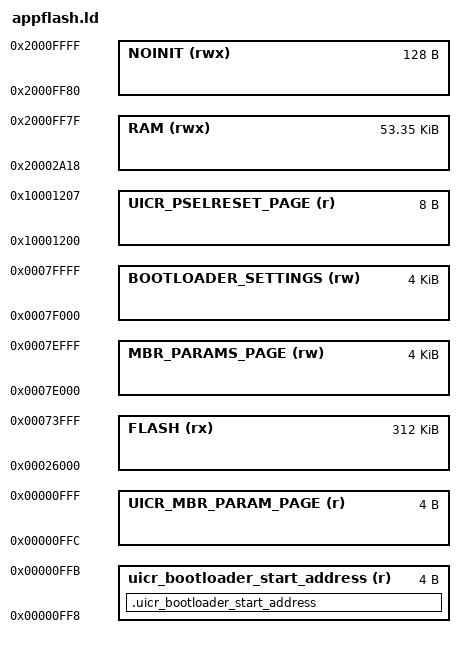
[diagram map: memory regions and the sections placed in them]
/*
 * application specific linker script (starts at 0X2080 (ram) 0x1f000 (Flash) )
 */

SEARCH_DIR(.)
GROUP(-lgcc -lc -lnosys)

MEMORY
{
  FLASH (rx) : ORIGIN = 0x26000, LENGTH = 0x4E000

  /**
   * Leave 80 bytes to the end of RAM for over reset info (NOINIT)
   */
  RAM (rwx) :  ORIGIN = 0x20002A18, LENGTH = 0xD568

  /** Location of non initialized RAM. Non initialized RAM is used for exchanging bond information
   *  from application to bootloader when using buttonluss DFU OTA.
   */
  NOINIT (rwx) :  ORIGIN = 0x2000FF80, LENGTH = 0x80

  /** Location of bootloader setting in flash. */
  BOOTLOADER_SETTINGS (rw) : ORIGIN = 0x0007F000, LENGTH = 0x1000

  /** Location in UICR where bootloader start address is stored. */
  uicr_bootloader_start_address (r) : ORIGIN = 0x00000FF8, LENGTH = 0x4

  /** Location of mbr params page in flash. */
  MBR_PARAMS_PAGE (rw) : ORIGIN = 0x0007E000, LENGTH = 0x1000

  /** Location in UICR where mbr params page address is stored. */
  UICR_MBR_PARAM_PAGE(r) : ORIGIN = 0x00000FFC, LENGTH = 0x04

  /** Location in UICR where PSELRESET params settings are stored. */
  UICR_PSELRESET_PAGE(r) : ORIGIN = 0x10001200, LENGTH = 0x08
}

SECTIONS
{
  . = ALIGN(4);
  .uicr_bootloader_start_address :
  {
    PROVIDE(__start_uicr_bootloader_start_address = .);
    KEEP(*(SORT(.uicr_bootloader_start_address*)))
    PROVIDE(__stop_uicr_bootloader_start_address = .);
  } > uicr_bootloader_start_address
}

SECTIONS
{
  /* Place the bootloader settings page in flash. */
  .bootloaderSettings(NOLOAD) :
  {

  } > BOOTLOADER_SETTINGS

  /* Place the mbr params page in flash. */
    .mbrParamsPage(NOLOAD) :
  {

  } > MBR_PARAMS_PAGE

  /* Write the bootloader address in UICR. */
  .uicrMbrParamsPageAddress :
  {
    KEEP(*(.uicrMbrParamsPageAddress))
  } > UICR_MBR_PARAM_PAGE


  /* Write RESET pin settings (dissable RESET pin) in UICR */
  .uicrPselresetPage :
  {
    KEEP(*(.uicrPselresetPage))
  } > UICR_PSELRESET_PAGE

  /* No init RAM section. Used for stuff like timestorage & faultcom. */
  .timestorage(NOLOAD) :
  {
  } > NOINIT
  .faultcom(NOLOAD) :
  {
  } > NOINIT

  .fs_data :
  {
    PROVIDE(__start_fs_data = .);
    KEEP(*(.fs_data))
    PROVIDE(__stop_fs_data = .);
  } > RAM
} INSERT AFTER .data;


SECTIONS
{
  . = ALIGN(4);
  .mem_section_dummy_ram :
  {
  }
  .log_dynamic_data :
  {
    PROVIDE(__start_log_dynamic_data = .);
    KEEP(*(SORT(.log_dynamic_data*)))
    PROVIDE(__stop_log_dynamic_data = .);
  } > RAM
  .log_filter_data :
  {
    PROVIDE(__start_log_filter_data = .);
    KEEP(*(SORT(.log_filter_data*)))
    PROVIDE(__stop_log_filter_data = .);
  } > RAM
  .cli_sorted_cmd_ptrs :
  {
    PROVIDE(__start_cli_sorted_cmd_ptrs = .);
    KEEP(*(.cli_sorted_cmd_ptrs))
    PROVIDE(__stop_cli_sorted_cmd_ptrs = .);
  } > RAM
  .fs_data :
  {
    PROVIDE(__start_fs_data = .);
    KEEP(*(.fs_data))
    PROVIDE(__stop_fs_data = .);
  } > RAM

} INSERT AFTER .data;

SECTIONS
{
  .mem_section_dummy_rom :
  {
  }
  .sdh_ant_observers :
  {
    PROVIDE(__start_sdh_ant_observers = .);
    KEEP(*(SORT(.sdh_ant_observers*)))
    PROVIDE(__stop_sdh_ant_observers = .);
  } > FLASH
  .sdh_ble_observers :
  {
    PROVIDE(__start_sdh_ble_observers = .);
    KEEP(*(SORT(.sdh_ble_observers*)))
    PROVIDE(__stop_sdh_ble_observers = .);
  } > FLASH
  .sdh_soc_observers :
  {
    PROVIDE(__start_sdh_soc_observers = .);
    KEEP(*(SORT(.sdh_soc_observers*)))
    PROVIDE(__stop_sdh_soc_observers = .);
  } > FLASH
  .sdh_req_observers :
  {
    PROVIDE(__start_sdh_req_observers = .);
    KEEP(*(SORT(.sdh_req_observers*)))
    PROVIDE(__stop_sdh_req_observers = .);
  } > FLASH
  .sdh_state_observers :
  {
    PROVIDE(__start_sdh_state_observers = .);
    KEEP(*(SORT(.sdh_state_observers*)))
    PROVIDE(__stop_sdh_state_observers = .);
  } > FLASH
  .sdh_stack_observers :
  {
    PROVIDE(__start_sdh_stack_observers = .);
    KEEP(*(SORT(.sdh_stack_observers*)))
    PROVIDE(__stop_sdh_stack_observers = .);
  } > FLASH
  .log_const_data :
  {
    PROVIDE(__start_log_const_data = .);
    KEEP(*(SORT(.log_const_data*)))
    PROVIDE(__stop_log_const_data = .);
  } > FLASH
    .nrf_balloc :
  {
    PROVIDE(__start_nrf_balloc = .);
    KEEP(*(.nrf_balloc))
    PROVIDE(__stop_nrf_balloc = .);
  } > FLASH
    .nrf_queue :
  {
    PROVIDE(__start_nrf_queue = .);
    KEEP(*(.nrf_queue))
    PROVIDE(__stop_nrf_queue = .);
  } > FLASH
    .cli_command :
  {
    PROVIDE(__start_cli_command = .);
    KEEP(*(.cli_command))
    PROVIDE(__stop_cli_command = .);
  } > FLASH
  .crypto_data :
  {
    PROVIDE(__start_crypto_data = .);
    KEEP(*(SORT(.crypto_data*)))
    PROVIDE(__stop_crypto_data = .);
  } > FLASH
  .pwr_mgmt_data :
  {
    PROVIDE(__start_pwr_mgmt_data = .);
    KEEP(*(SORT(.pwr_mgmt_data*)))
    PROVIDE(__stop_pwr_mgmt_data = .);
  } > FLASH
  .log_backends :
  {
    PROVIDE(__start_log_backends = .);
    KEEP(*(SORT(.log_backends*)))
    PROVIDE(__stop_log_backends = .);
  } > FLASH

} INSERT AFTER .text


INCLUDE common.ld
